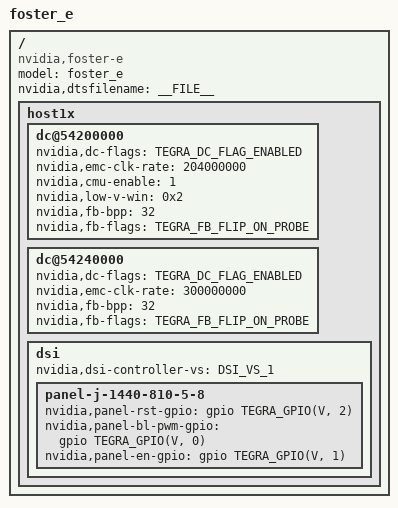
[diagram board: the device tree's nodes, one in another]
/*
 * arch/arm64/boot/dts/tegra210-foster-e-p2530-0032-e00-00.dts
 *
 * Copyright (c) 2014, NVIDIA CORPORATION.  All rights reserved.
 *
 * This program is free software; you can redistribute it and/or modify
 * it under the terms of the GNU General Public License as published by
 * the Free Software Foundation; version 2 of the License.
 *
 * This program is distributed in the hope that it will be useful, but WITHOUT
 * ANY WARRANTY; without even the implied warranty of MERCHANTABILITY or
 * FITNESS FOR A PARTICULAR PURPOSE.  See the GNU General Public License for
 * more details.
 *
 * You should have received a copy of the GNU General Public License along
 * with this program; if not, write to the Free Software Foundation, Inc.,
 * 51 Franklin Street, Fifth Floor, Boston, MA  02110-1301, USA.
 *
 */

/dts-v1/;

/memreserve/ 0x80000000 0x00020000;

#include "tegra210-ers-common.dtsi"
#include "tegra210-platforms/tegra210-loki-e-p2530-common.dtsi"
#include "tegra210-platforms/tegra210-ers-extgpio-e2141-1100-a00.dtsi"
#include "tegra210-platforms/tegra210-loki-power-tree-p2530-0999-e00.dtsi"

#include "tegra210-platforms/tegra210-loki-e-gpio-p2530-0032-e00.dtsi"
#include "tegra210-platforms/tegra210-loki-e-pinmux-p2530-0032-e00.dtsi"
#include "tegra210-platforms/tegra210-comms.dtsi"
#include "tegra210-platforms/tegra210-foster-e-pwm-fan.dtsi"
#include "tegra210-platforms/tegra210-loki-sdhci.dtsi"
#include "tegra210-platforms/tegra210-ers-hdmi-e2190-1100-a00.dtsi"
#include "panel-j-1440-810-5-8.dtsi"
#include "tegra210-platforms/tegra210-foster-e-thermal-fan-est.dtsi"

/ {
	model = "foster_e";
	compatible = "nvidia,foster-e", "nvidia,tegra210";
	nvidia,dtsfilename = __FILE__;

	host1x {
		/* tegradc.0 */
		dc@54200000 {
			status = "okay";
			nvidia,dc-flags = <TEGRA_DC_FLAG_ENABLED>;
			nvidia,emc-clk-rate = <204000000>;
			nvidia,cmu-enable = <1>;
			nvidia,low-v-win = <0x2>;
			nvidia,fb-bpp = <32>; /* bits per pixel */
			nvidia,fb-flags = <TEGRA_FB_FLIP_ON_PROBE>;
		};
		/* tegradc.1 */
		dc@54240000 {
			status = "okay";
			nvidia,dc-flags = <TEGRA_DC_FLAG_ENABLED>;
			nvidia,emc-clk-rate = <300000000>;
			nvidia,fb-bpp = <32>; /* bits per pixel */
			nvidia,fb-flags = <TEGRA_FB_FLIP_ON_PROBE>;
		};

		dsi {
			nvidia,dsi-controller-vs = <DSI_VS_1>;
			status = "okay";
			panel-j-1440-810-5-8 {
				nvidia,panel-rst-gpio = <&gpio TEGRA_GPIO(V, 2) 0>; /* PV2 */
				nvidia,panel-bl-pwm-gpio = <&gpio TEGRA_GPIO(V, 0) 0>; /* PV0 */
				nvidia,panel-en-gpio = <&gpio TEGRA_GPIO(V, 1) 0>; /* PV1 */
			};
		};
	};

};

